# RS14100 register map
File version: 1.0
CPU: CM4 r0p1, little endian, MPU, FPU, 4 interrupt priority bits
Registers are 32-bit, read-write, reset 0x0 unless marked. A register's access mark holds for its fields unless they carry their own. Offsets are from the block's base; [hi:lo] are bit positions; {n}, {i} and the like mark numbered series; 'fields as' and 'values as' point back to an identical list.

## UDMA0 — DMA Performs data transfers along with Addresses and control information
Base 0x44030000
Same registers: UDMA1 0x24043000
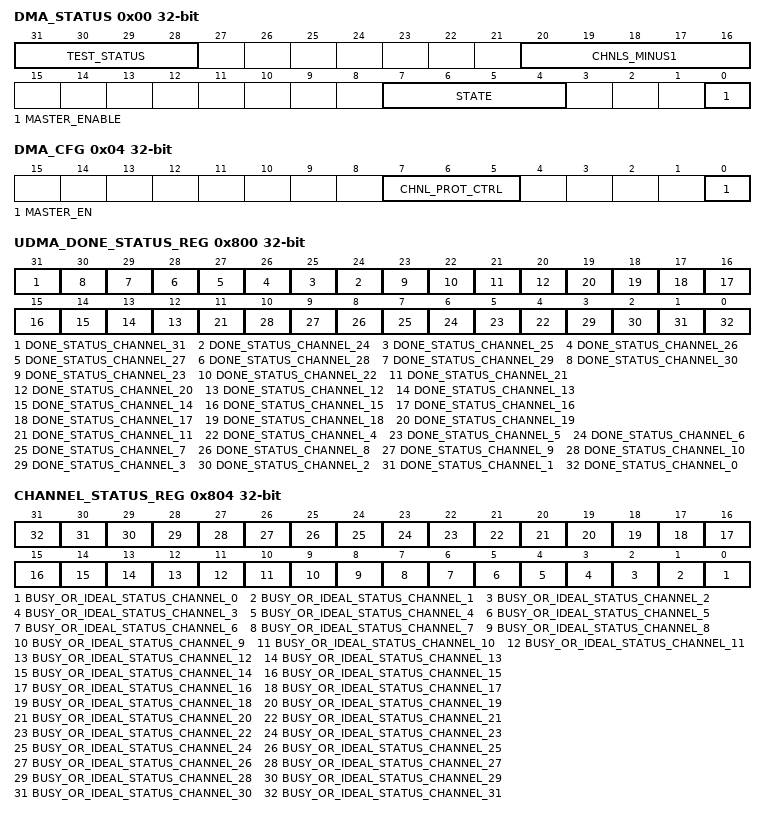
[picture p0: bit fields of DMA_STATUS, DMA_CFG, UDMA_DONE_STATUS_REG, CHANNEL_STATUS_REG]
0x00 DMA_STATUS ro — UDMA Status Register
  [31:28] TEST_STATUS — To reduce the gate count you can configure the controller
    0=Controller does not includes integration test logic; 1=Controller does not includes integration test logic
  [20:16] CHNLS_MINUS1 — Number of available DMA channels minus one
  [7:4] STATE — Current state of the control state machine
  [0] MASTER_ENABLE — Enable status of controller
    0=Disable (controller is disable); 1=Enable (controller is enable)
0x04 DMA_CFG wo reset not defined — DMA Configuration
  [7:5] CHNL_PROT_CTRL — Sets the AHB-Lite protection by controlling the HPROT[3:1]] signal levels as follows Bit[7]-Controls HPROT[3] to indicate if cacheable access is occurring Bit[6]-Controls HPROT[2] to indicate if cacheable access is occurring Bit[5]-Controls HPROT[1] to indicate if cacheable access is occurring
  [0] MASTER_EN — Enable for the controller
    values as DMA_STATUS.MASTER_ENABLE
0x08 CTRL_BASE_PTR — Channel Control Data Base Pointer
  [31:10] CTRL_BASE_PTR — Pointer to the base address of the primary data structure
0x0C ALT_CTRL_BASE_PTR ro — Channel Alternate Control Data Base Pointer
  [31:0] ALT_CTRL_BASE_PTR — Base address of the alternative data structure
0x10 DMA_WAITONREQUEST_STATUS ro — Channel Wait on request status register
  [31:0] DMA_WAITONREQ_STATUS — Per Channel wait on request status
    0=disabled (Bit [C] = 0 dma_waitonreq[C] is LOW (where C specifies channel number)); 1=enabled (Bit [C] = 1 dma_waitonreq[C] is HIGH(where C specifies channel number))
0x14 CHNL_SW_REQUEST wo reset not defined — Channel Software Request
  [31:0] CHNL_SW_REQUEST — Set the appropriate bit to generate a software DMA request on the corresponding DMA channel
    0=disabled (Bit [C] = 0 Does not create a DMA request for channel C); 1=enabled (Bit [C] = 1 Creates a DMA request for channel C)
0x18 CHNL_USEBURST_SET — UDMA Channel use burst set
  [31:0] CHNL_USEBURST_SET — The use burst status, or disables dma_sreq[C] from generating DMA requests.
    0=disabled (Read as:Bit [C] = 0 DMA channel C responds to requests that it receives on dma_req[C] or dma_sreq[C]. The controller performs 2R, or single, bus transfer Write as:Bit [C] = 0 No effect. Use the chnl_useburst_clr Register to set bit [C] to 0); 1=enabled (Read as:Bit [C] = 1 DMA channel C does not respond to requests that it receives ondma_sreq[C] The controller only responds to dma_req[C] requests and performs 2R transfers Write as:Bit [C] = 1 Disables dma_sreq[C] from generating DMA requests. The controller performs 2R transfers)
0x1C CHNL_USEBURST_CLR wo reset not defined — UDMA Channel use burst clear
  [31:0] CHNL_USEBURST_CLR — Set the appropriate bit to enable dma_sreq[] to generate requests
    0=disabled (Bit [C] = 0 No effect. Use the chnl_useburst_set Register to disable dma_sreq[] from generating requests); 1=enabled (Bit [C] = 1 Enables dma_sreq[C] to generate DMA requests)
0x20 CHNL_REQ_MASK_SET — UDMA Channel request mask set Register
  [31:0] CHNL_REQ_MASK_SET — Returns the request mask status of dma_req[] and dma_sreq[], or disables the corresponding channel from generating DMA requests
    0=disabled (Read as:Bit [C] = 0 External requests are enabled for channel C Write as:Bit [C] = 0 No effect. Use the chnl_req_mask_clr Register to enable DMA requests); 1=enabled (Read as:Bit [C] = Bit [C] = 1 External requests are disabled for channel C Write as:Bit [C] =Bit [C] = 1 Disables dma_req[C] and dma_sreq[C] from generating DMA requests)
0x24 CHNL_REQ_MASK_CLR wo reset not defined — UDMA Channel request mask clear
  [31:0] CHNL_REQ_MASK_CLR — Set the appropriate bit to enable DMA requests for the channel corresponding to dma_req[] and dma_sreq[]
    0=disabled (Bit [C] = 0 No effect Use the chnl_req_mask_set Register to disable dma_req[] and dma_sreq[] from generating requests); 1=enabled (Bit [C] = 1 Enables dma_req[C] or dma_sreq[C] to generate DMA requests)
0x28 CHNL_ENABLE_SET — UDMA Channel enable register
  [31:0] CHNL_ENABLE_SET — This Bits are Used to Load the 16bits of Source address
    0=disabled (Read as:Bit [C] = 0 Channel C is disabled Write as:Bit [C] = 0 No effect. Use the chnl_enable_clr Register to disable a channel); 1=enabled (Read as:Bit [C] = 1 Channel C is enabled Write as:Bit [C] = 1 Enables channel C)
0x2C CHNL_ENABLE_CLR wo reset not defined — UDMA Channel enable clear register
  [31:0] CHNL_ENABLE_CLR — Set the appropriate bit to disable the corresponding DMA channel
    0=disabled (Bit [C] = 0 No effect); 1=enabled (Bit [C] = 1 Disables channel C)
0x30 CHNL_PRI_ALT_SET — UDMA Channel primary or alternate set
  [31:0] CHNL_PRI_ALT_SET — Returns the channel control data structure status or selects the alternate data structure for the corresponding DMA channel
    0=disabled (Read as:Bit [C] = 0 DMA channel C is using the primary data structure Write as:Bit [C] = 0 No effect. Use the chnl_pri_alt_clr Register to set bit [C] to 0); 1=enabled (Read as:Bit [C] = 1 DMA channel C is using the alternate data structure Write as:Bit [C] = 1 Selects the alternate data structure for channel C)
0x34 CHNL_PRI_ALT_CLR wo reset not defined — UDMA Channel primary alternate clear
  [31:0] CHNL_PRI_ALT_CLR — Set the appropriate bit to select the primary data structure for the corresponding DMA channel
    0=disabled (Bit [C] = 0 No effect); 1=enabled (Bit [C] = 1 Selects the primary data structure for channel C)
0x38 CHNL_PRIORITY_SET — UDMA Channel Priority Set
  [0] CHNL_PRIORITY_SET — Set the appropriate bit to select the primary data structure for the corresponding DMA channel
    values as CHNL_PRI_ALT_CLR.CHNL_PRI_ALT_CLR
0x3C CHNL_PRIORITY_CLR wo reset not defined — UDMA Channel Priority Clear
  [31:0] CHNL_PRIORITY_CLR — Set the appropriate bit to select the default priority level for the specified DMA channel
    0=disabled (Bit [C] = 0 No effect); 1=enabled (Bit [C] = 1 Channel C uses the default priority level)
0x4C ERR_CLR — UDMA Bus Error Clear Register
  [0] ERR_CLR — Returns the status of dma_err
    0=disabled (Read as:0 = dma_err is LOW Write as:0 = No effect, status of dma_err is unchanged); 1=enabled (Read as:1 = dma_err is HIGH Write as:1 = Sets dma_err LOW)
0x800 UDMA_DONE_STATUS_REG — UDMA Done status Register
  [31] DONE_STATUS_CHANNEL_31 — UDMA done Status of the channel 31
    0=disabled (Write as:0 will have no effect); 1=enabled (Read as:1 indicates the transfer is completed for channel 31st Write as:1 will clear the bit)
  [n] DONE_STATUS_CHANNEL_{n} (n=24..30) — UDMA done Status of the channel {n}
    0=disabled (Write as:0 will have no effect); 1=enabled (Read as:1 indicates the transfer is completed for channel {n}th Write as:1 will clear the bit)
  [23] DONE_STATUS_CHANNEL_23 — UDMA done Status of the channel 23
    0=disabled (Write as:0 will have no effect); 1=enabled (Read as:1 indicates the transfer is completed for channel 23rd Write as:1 will clear the bit)
  [22] DONE_STATUS_CHANNEL_22 — UDMA done Status of the channel 22
    0=disabled (Write as:0 will have no effect); 1=enabled (Read as:1 indicates the transfer is completed for channel 22th Write as:1 will clear the bit)
  [21] DONE_STATUS_CHANNEL_21 — UDMA done Status of the channel 21
    0=disabled (Write as:0 will have no effect); 1=enabled (Read as:1 indicates the transfer is completed for channel 21th Write as:1 will clear the bit)
  [20] DONE_STATUS_CHANNEL_20 — UDMA done Status of the channel 3
    0=disabled (Write as:0 will have no effect); 1=enabled (Read as:1 indicates the transfer is completed for channel 20th Write as:1 will clear the bit)
  [n] DONE_STATUS_CHANNEL_{n} (n=12..19) — UDMA done Status of the channel {n}
    values as DONE_STATUS_CHANNEL_24
  [11] DONE_STATUS_CHANNEL_11 — UDMA done Status of the channel 3
    0=disabled (Write as:0 will have no effect); 1=enabled (Read as:1 indicates the transfer is completed for channel 11th Write as:1 will clear the bit)
  [n] DONE_STATUS_CHANNEL_{n} (n=4..10) — UDMA done Status of the channel {n}
    values as DONE_STATUS_CHANNEL_24
  [3] DONE_STATUS_CHANNEL_3 — UDMA done Status of the channel 3
    0=disabled (Write as:0 will have no effect); 1=enabled (Read as:1 indicates the transfer is completed for channel 3rd Write as:1 will clear the bit)
  [2] DONE_STATUS_CHANNEL_2 — UDMA done Status of the channel 2
    0=disabled (Write as:0 will have no effect); 1=enabled (Read as:1 indicates the transfer is completed for channel 2nd Write as:1 will clear the bit)
  [1] DONE_STATUS_CHANNEL_1 — UDMA done Status of the channel 1
    0=disabled (Write as:0 will have no effect); 1=enabled (Read as:1 indicates the transfer is completed for channel 1st Write as:1 will clear the bit)
  [0] DONE_STATUS_CHANNEL_0 — UDMA done Status of the channel 0
    0=disabled (Write as:0 will have no effect); 1=enabled (Read as:1 indicates the transfer is completed for channel 0th Write as:1 will clear the bit)
0x804 CHANNEL_STATUS_REG — Channel status Register
  [n] BUSY_OR_IDEAL_STATUS_CHANNEL_{n} (n=0..31) — Reading 1 indicates that the channel {n} is busy
0x808 PERIPHERAL_SELECT_CHANNEL0_REG (reset mask 0x1F) — Peripheral Select Channel0 register
  [5:0] PERIPHERAL_SELECT_CHANNEL0 — Selects which peripheral will be selected for the channel 0
0x80C PERIPHERAL_SELECT_CHANNEL1 (reset mask 0x1F)
  [5:0] PERIPHERAL_SELECT_CHANNEL1 — Selects which peripheral will be selected for the channel 1
0x810 PERIPHERAL_SELECT_CHANNEL2 (reset mask 0x1F)
  [5:0] PERIPHERAL_SELECT_CHANNEL2 — Selects which peripheral will be selected for the channel 2
0x814 PERIPHERAL_SELECT_CHANNEL3 (reset mask 0x1F)
  [5:0] PERIPHERAL_SELECT_CHANNEL2 — Selects which peripheral will be selected for the channel 3
0x818 PERIPHERAL_SELECT_CHANNEL4 (reset mask 0x1F)
  [5:0] PERIPHERAL_SELECT_CHANNEL4 — Selects which peripheral will be selected for the channel 4
0x81C PERIPHERAL_SELECT_CHANNEL5 (reset mask 0x1F)
  [5:0] PERIPHERAL_SELECT_CHANNEL5 — Selects which peripheral will be selected for the channel 3
0x820 PERIPHERAL_SELECT_CHANNEL6 (reset mask 0x1F)
  [5:0] PERIPHERAL_SELECT_CHANNEL6 — Selects which peripheral will be selected for the channel 6
0x824 PERIPHERAL_SELECT_CHANNEL7 (reset mask 0x1F)
  [5:0] PERIPHERAL_SELECT_CHANNEL7 — Selects which peripheral will be selected for the channel 7
0x828 UDMA_CONFIG_CTRL_REG 16-bit — DMA Controller Transfer Length Register
  [0] SINGLE_REQUEST_ENABLE — Enabled signal for single request
    0=disabled (Single request will be disabled); 1=enabled (Single request will be enabled)
